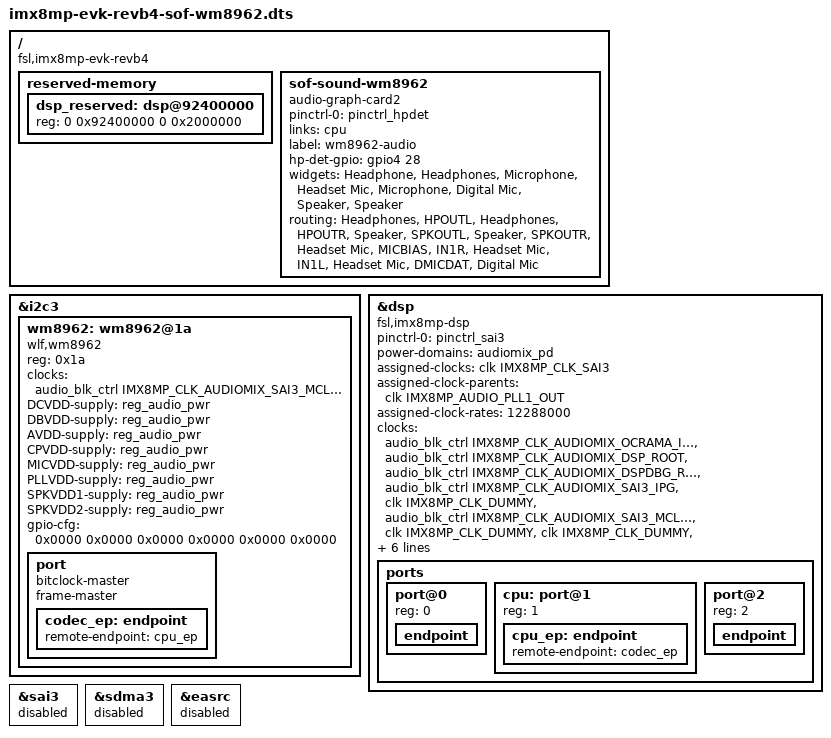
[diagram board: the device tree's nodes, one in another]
// SPDX-License-Identifier: GPL-2.0+
/*
 * Copyright 2023 NXP
 */

#include "imx8mp-evk.dts"

/delete-node/ &dsp_reserved_heap;
/delete-node/ &dsp_vdev0vring0;
/delete-node/ &dsp_vdev0vring1;
/delete-node/ &dsp_vdev0buffer;
/delete-node/ &wm8960;

/ {
	compatible = "fsl,imx8mp-evk-revb4", "fsl,imx8mp";

	/delete-node/ sound-wm8960;

	reserved-memory {
		dsp_reserved: dsp@92400000 {
			reg = <0 0x92400000 0 0x2000000>;
		};
	};

	sof-sound-wm8962 {
		compatible = "audio-graph-card2";
		pinctrl-names = "default";
		pinctrl-0 = <&pinctrl_hpdet>;
		links = <&cpu>;
		label = "wm8962-audio";
		hp-det-gpio = <&gpio4 28 0>;
		widgets =
			"Headphone", "Headphones",
			"Microphone", "Headset Mic",
			"Microphone", "Digital Mic",
			"Speaker", "Speaker";
		routing =
			"Headphones", "HPOUTL",
			"Headphones", "HPOUTR",
			"Speaker", "SPKOUTL",
			"Speaker", "SPKOUTR",
			"Headset Mic", "MICBIAS",
			"IN1R", "Headset Mic",
			"IN1L", "Headset Mic",
			"DMICDAT", "Digital Mic";
	};
};

&i2c3 {
	#address-cells = <1>;
	#size-cells = <0>;

	wm8962: wm8962@1a {
		compatible = "wlf,wm8962";
		reg = <0x1a>;
		clocks = <&audio_blk_ctrl IMX8MP_CLK_AUDIOMIX_SAI3_MCLK1>;
		DCVDD-supply = <&reg_audio_pwr>;
		DBVDD-supply = <&reg_audio_pwr>;
		AVDD-supply = <&reg_audio_pwr>;
		CPVDD-supply = <&reg_audio_pwr>;
		MICVDD-supply = <&reg_audio_pwr>;
		PLLVDD-supply = <&reg_audio_pwr>;
		SPKVDD1-supply = <&reg_audio_pwr>;
		SPKVDD2-supply = <&reg_audio_pwr>;
		gpio-cfg = <
			0x0000 /* 0:Default */
			0x0000 /* 1:Default */
			0x0000 /* 2:FN_DMICCLK */
			0x0000 /* 3:Default */
			0x0000 /* 4:FN_DMICCDAT */
			0x0000 /* 5:Default */
		>;
	};
};

&dsp {
	compatible = "fsl,imx8mp-dsp";

	pinctrl-names = "default";
	pinctrl-0 = <&pinctrl_sai3>;

	power-domains = <&audiomix_pd>;

	assigned-clocks = <&clk IMX8MP_CLK_SAI3>;
	assigned-clock-parents = <&clk IMX8MP_AUDIO_PLL1_OUT>;
	assigned-clock-rates = <12288000>;
	clocks = <&audio_blk_ctrl IMX8MP_CLK_AUDIOMIX_OCRAMA_IPG>,
		<&audio_blk_ctrl IMX8MP_CLK_AUDIOMIX_DSP_ROOT>,
		<&audio_blk_ctrl IMX8MP_CLK_AUDIOMIX_DSPDBG_ROOT>,
		<&audio_blk_ctrl IMX8MP_CLK_AUDIOMIX_SAI3_IPG>, <&clk IMX8MP_CLK_DUMMY>,
		<&audio_blk_ctrl IMX8MP_CLK_AUDIOMIX_SAI3_MCLK1>, <&clk IMX8MP_CLK_DUMMY>,
		<&clk IMX8MP_CLK_DUMMY>,
		<&audio_blk_ctrl IMX8MP_CLK_AUDIOMIX_SDMA3_ROOT>;

	clock-names = "ipg", "ocram", "core",
		"sai3_bus", "sai3_mclk0", "sai3_mclk1", "sai3_mclk2", "sai3_mclk3",
		"sdma3_root";

	mbox-names = "txdb0", "txdb1", "rxdb0", "rxdb1";
	mboxes = <&mu2 2 0>, <&mu2 2 1>,
		 <&mu2 3 0>, <&mu2 3 1>;
	memory-region = <&dsp_reserved>;
	/delete-property/ firmware-name;

	tplg-name = "sof-imx8mp-wm8962.tplg";
	machine-drv-name = "asoc-audio-graph-card2";
	status = "okay";

	ports {
		#address-cells = <1>;
		#size-cells = <0>;

		port@0 { reg = <0>; endpoint { /* not used */ }; };
		cpu: port@1 { reg = <1>; cpu_ep: endpoint { remote-endpoint = <&codec_ep>; }; };
		port@2 { reg = <2>; endpoint { /* not used */ }; };
	};
};

&wm8962 {
	status = "okay";
	port {
		bitclock-master;
		frame-master;
		codec_ep: endpoint { remote-endpoint = <&cpu_ep>; };
	};
};

&sai3 {
	status = "disabled";
};

&sdma3 {
	status = "disabled";
};

&easrc {
	status = "disabled";
};
